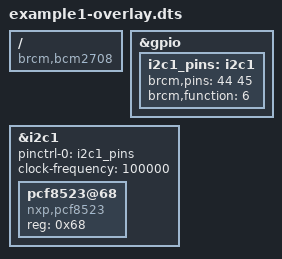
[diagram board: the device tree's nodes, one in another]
// Example overlay for PCF8523 RTC device
/dts-v1/;
/plugin/;

/ {
  compatible = "brcm,bcm2708";

  //
  // Set up GPIOs:
  //  I2C1 on GPIO44,45
  //
  fragment@0 {
    target = <&gpio>;
    __overlay__ {
      i2c1_pins: i2c1 {
        brcm,pins = <44 45>;
        brcm,function = <6>; /* alt2 */
      };
    };
  };

  //
  // I2C Device(s)
  //
  fragment@1 {
    target = <&i2c1>;
    __overlay__ {
      #address-cells = <1>; /* needed to avoid dtc warning */
      #size-cells = <0>; /* needed to avoid dtc warning */
      pinctrl-names = "default";
      pinctrl-0 = <&i2c1_pins>;
      clock-frequency = <100000>;
      status = "okay";
      // PCF8523 RTC device
      pcf8523@68 { 
        compatible = "nxp,pcf8523";
        reg = <0x68>;
        status = "okay";
      };
    };
  };


};
